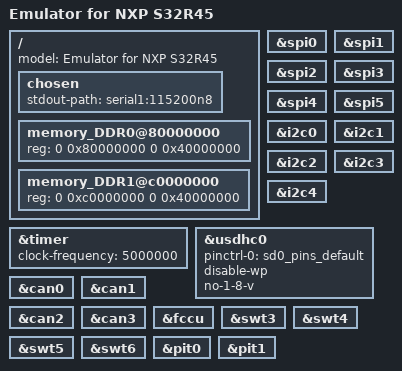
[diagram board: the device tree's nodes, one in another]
// SPDX-License-Identifier: GPL-2.0-or-later OR MIT
/*
 * Copyright 2019-2020, 2023-2024 NXP
 */

/dts-v1/;
#include "s32r45.dtsi"

/ {
	model = "Emulator for NXP S32R45";

	chosen {
		stdout-path = "serial1:115200n8";
	};

	memory_DDR0@80000000 {
		device_type = "memory";
		reg = <0 0x80000000 0 0x40000000>;
	};

	memory_DDR1@c0000000 {
		device_type = "memory";
		reg = <0 0xc0000000 0 0x40000000>;
	};
};

&timer {
	clock-frequency = <5000000>;
};

&spi0 {
	status = "okay";
};

&spi1 {
	status = "okay";
};

&spi2 {
	status = "okay";
};

&spi3 {
	status = "okay";
};

&spi4 {
	status = "okay";
};

&spi5 {
	status = "okay";
};

&i2c0 {
	status = "okay";
};

&i2c1 {
	status = "okay";
};

&i2c2 {
	status = "okay";
};

&i2c3 {
	status = "okay";
};

&i2c4 {
	status = "okay";
};

&usdhc0 {
	pinctrl-names = "default";
	pinctrl-0 = <&sd0_pins_default>;
	disable-wp;
	no-1-8-v;
	status = "okay";
};

&can0 {
	status = "okay";
};

&can1 {
	status = "okay";
};

&can2 {
	status = "okay";
};

&can3 {
	status = "okay";
};

&fccu {
	status = "okay";
};

&swt3 {
	status = "okay";
};

&swt4 {
	status = "okay";
};

&swt5 {
	status = "okay";
};

&swt6 {
	status = "okay";
};

&pit0 {
	status = "okay";
};

&pit1 {
	status = "okay";
};
